VERSION ""

NS_ :

BS_:

BU_: INV VCU BMS U2C

BO_ 3221225472 VECTOR__INDEPENDENT_SIG_MSG: 0 Vector__XXX
 SG_ INV_Buffer_Record : 0|8@1+ (1,0) [0|255] "" Vector__XXX
 SG_ INV_Buffer_Segment : 8|8@1+ (1,0) [0|5] "" Vector__XXX
 SG_ INV_Diag_Data_1 : 16|16@1- (1,0) [-32768|32767] "" Vector__XXX
 SG_ INV_Diag_Data_2 : 32|16@1- (1,0) [-32768|32767] "" Vector__XXX
 SG_ INV_Diag_Data_3 : 48|16@1- (1,0) [-32768|32767] "" Vector__XXX

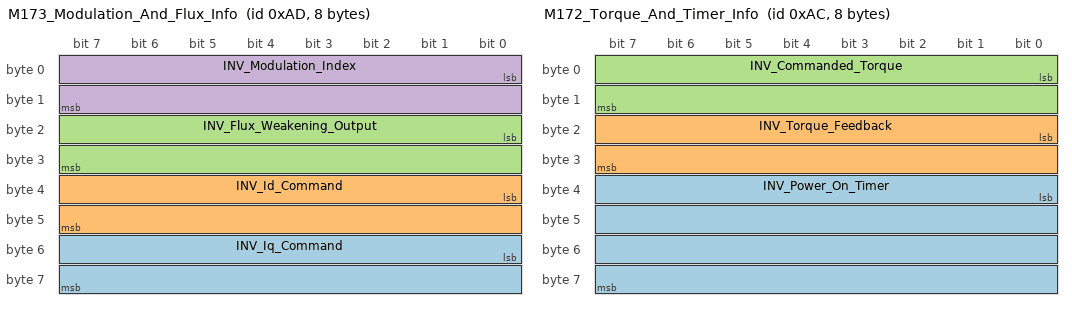
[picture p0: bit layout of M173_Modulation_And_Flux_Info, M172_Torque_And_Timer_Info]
BO_ 173 M173_Modulation_And_Flux_Info: 8 INV
 SG_ INV_Iq_Command : 48|16@1- (0.1,0) [-3276.8|3276.7] "current:A" VCU_Inverter_Ext
 SG_ INV_Id_Command : 32|16@1- (0.1,0) [-3276.8|3276.7] "current:A" VCU_Inverter_Ext
 SG_ INV_Flux_Weakening_Output : 16|16@1- (0.1,0) [-3276.8|3276.7] "current:A" VCU_Inverter_Ext
 SG_ INV_Modulation_Index : 0|16@1- (0.0001,0) [0|3.2767] "" VCU_Inverter_Ext

BO_ 172 M172_Torque_And_Timer_Info: 8 INV
 SG_ INV_Power_On_Timer : 32|32@1+ (0.003,0) [0|12884800] "time:sec" VCU_Inverter_Ext
 SG_ INV_Torque_Feedback : 16|16@1- (0.1,0) [-3276.8|3276.7] "torque:N.m" VCU_Inverter_Ext
 SG_ INV_Commanded_Torque : 0|16@1- (0.1,0) [-3276.8|3276.7] "torque:N.m" VCU_Inverter_Ext

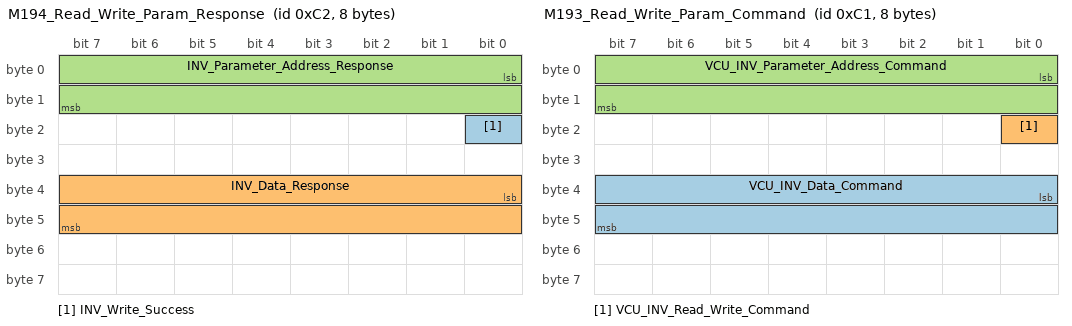
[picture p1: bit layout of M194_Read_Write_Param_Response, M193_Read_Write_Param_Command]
BO_ 194 M194_Read_Write_Param_Response: 8 INV
 SG_ INV_Write_Success : 16|1@1+ (1,0) [0|1] "" VCU_Inverter_Ext
 SG_ INV_Data_Response : 32|16@1- (1,0) [-32768|32767] "" VCU_Inverter_Ext
 SG_ INV_Parameter_Address_Response : 0|16@1+ (1,0) [0|65535] "" VCU_Inverter_Ext

BO_ 193 M193_Read_Write_Param_Command: 8 VCU
 SG_ VCU_INV_Data_Command : 32|16@1- (1,0) [-32768|32767] "" INV
 SG_ VCU_INV_Read_Write_Command : 16|1@1+ (1,0) [0|1] "" INV
 SG_ VCU_INV_Parameter_Address_Command : 0|16@1+ (1,0) [0|65535] "" INV

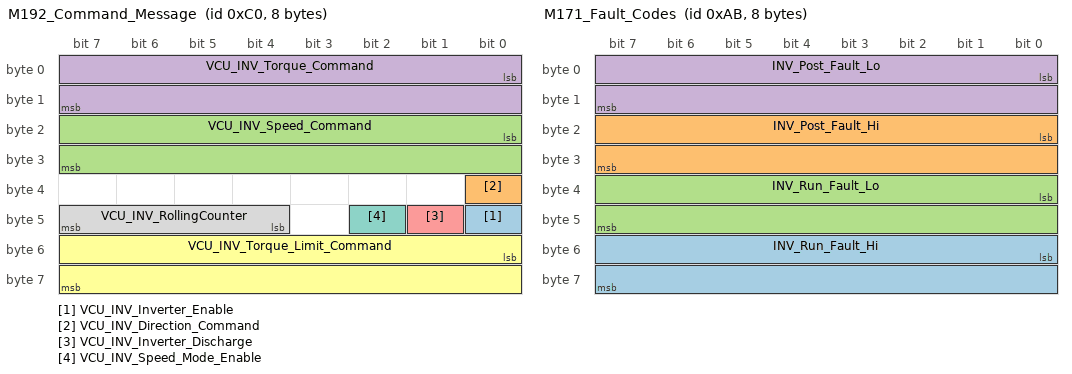
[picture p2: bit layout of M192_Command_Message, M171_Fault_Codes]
BO_ 192 M192_Command_Message: 8 VCU
 SG_ VCU_INV_Inverter_Enable : 40|1@1+ (1,0) [0|1] "Bit" INV
 SG_ VCU_INV_Direction_Command : 32|1@1+ (1,0) [0|1] "Bit" INV
 SG_ VCU_INV_Speed_Command : 16|16@1- (1,0) [-32768|32767] "rpm" INV
 SG_ VCU_INV_Torque_Command : 0|16@1- (0.1,0) [-3276.8|3276.7] "torque:N.m" INV
 SG_ VCU_INV_Inverter_Discharge : 41|1@1+ (1,0) [0|1] "" INV
 SG_ VCU_INV_Torque_Limit_Command : 48|16@1- (0.1,0) [-3276.8|3276.7] "torque:N.m" INV
 SG_ VCU_INV_Speed_Mode_Enable : 42|1@1+ (1,0) [0|1] "" INV
 SG_ VCU_INV_RollingCounter : 44|4@1+ (1,0) [0|15] "" INV

BO_ 171 M171_Fault_Codes: 8 INV
 SG_ INV_Run_Fault_Hi : 48|16@1+ (1,0) [0|65535] "" VCU_Inverter_Ext
 SG_ INV_Post_Fault_Hi : 16|16@1+ (1,0) [0|65535] "" VCU_Inverter_Ext
 SG_ INV_Run_Fault_Lo : 32|16@1+ (1,0) [0|65535] "" VCU_Inverter_Ext
 SG_ INV_Post_Fault_Lo : 0|16@1+ (1,0) [0|65535] "" VCU_Inverter_Ext

BO_ 170 M170_Internal_States: 8 INV
 SG_ INV_Direction_Command : 56|1@1+ (1,0) [0|1] "" VCU_Inverter_Ext
 SG_ INV_Inverter_Enable_State : 48|1@1+ (1,0) [0|1] "" VCU_Inverter_Ext
 SG_ INV_Relay_3_Status : 26|1@1+ (1,0) [0|1] "" VCU_Inverter_Ext
 SG_ INV_Relay_4_Status : 27|1@1+ (1,0) [0|1] "" VCU_Inverter_Ext
 SG_ INV_Relay_2_Status : 25|1@1+ (1,0) [0|1] "" VCU_Inverter_Ext
 SG_ INV_Inverter_Run_Mode : 32|1@1+ (1,0) [0|1] "" VCU_Inverter_Ext
 SG_ INV_Inverter_Command_Mode : 40|1@1+ (1,0) [0|1] "" VCU_Inverter_Ext
 SG_ INV_Relay_1_Status : 24|1@1+ (1,0) [0|1] "" VCU_Inverter_Ext
 SG_ INV_Inverter_State : 16|8@1+ (1,0) [0|255] "" VCU_Inverter_Ext
 SG_ INV_VSM_State : 0|8@1+ (1,0) [0|15] "" VCU_Inverter_Ext
 SG_ INV_Inverter_Enable_Lockout : 55|1@1+ (1,0) [0|1] "" VCU_Inverter_Ext
 SG_ INV_Inverter_Discharge_State : 37|3@1+ (1,0) [0|7] "" VCU_Inverter_Ext
 SG_ INV_Relay_5_Status : 28|1@1+ (1,0) [0|1] "" VCU_Inverter_Ext
 SG_ INV_Relay_6_Status : 29|1@1+ (1,0) [0|1] "" VCU_Inverter_Ext
 SG_ INV_BMS_Active : 57|1@1+ (1,0) [0|1] "" VCU_Inverter_Ext
 SG_ INV_BMS_Torque_Limiting : 58|1@1+ (1,0) [0|1] "" VCU_Inverter_Ext
 SG_ INV_Max_Speed_Limiting : 59|1@1+ (1,0) [0|1] "" VCU_Inverter_Ext
 SG_ INV_Low_Speed_Limiting : 61|1@1+ (1,0) [0|1] "" VCU_Inverter_Ext
 SG_ INV_Rolling_Counter : 44|4@1+ (1,0) [0|15] "" VCU_Inverter_Ext
 SG_ INV_PWM_Frequency : 8|8@1+ (1,0) [0|255] "kHz" VCU_Inverter_Ext
 SG_ INV_Start_Mode_Active : 54|1@1+ (1,0) [0|1] "" VCU_Inverter_Ext

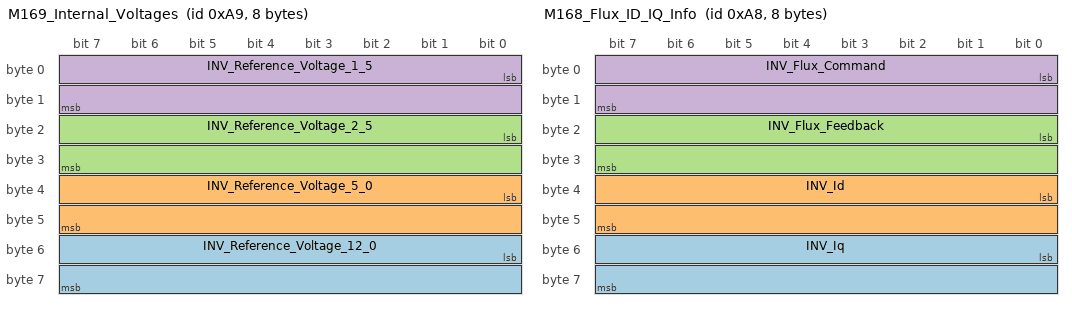
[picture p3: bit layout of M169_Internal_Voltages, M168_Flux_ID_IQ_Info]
BO_ 169 M169_Internal_Voltages: 8 INV
 SG_ INV_Reference_Voltage_12_0 : 48|16@1- (0.01,0) [-327.68|327.67] "voltage:V" VCU_Inverter_Ext
 SG_ INV_Reference_Voltage_5_0 : 32|16@1- (0.01,0) [-327.68|327.67] "voltage:V" VCU_Inverter_Ext
 SG_ INV_Reference_Voltage_2_5 : 16|16@1- (0.01,0) [-327.68|327.67] "voltage:V" VCU_Inverter_Ext
 SG_ INV_Reference_Voltage_1_5 : 0|16@1- (0.01,0) [-327.68|327.67] "voltage:V" VCU_Inverter_Ext

BO_ 168 M168_Flux_ID_IQ_Info: 8 INV
 SG_ INV_Iq : 48|16@1- (0.1,0) [-3276.8|3276.7] "current:A" VCU_Inverter_Ext
 SG_ INV_Id : 32|16@1- (0.1,0) [-3276.8|3276.7] "current:A" VCU_Inverter_Ext
 SG_ INV_Flux_Feedback : 16|16@1- (0.001,0) [-32.768|32.767] "flux:Wb" VCU_Inverter_Ext
 SG_ INV_Flux_Command : 0|16@1- (0.001,0) [-32.768|32.767] "flux:Wb" VCU_Inverter_Ext

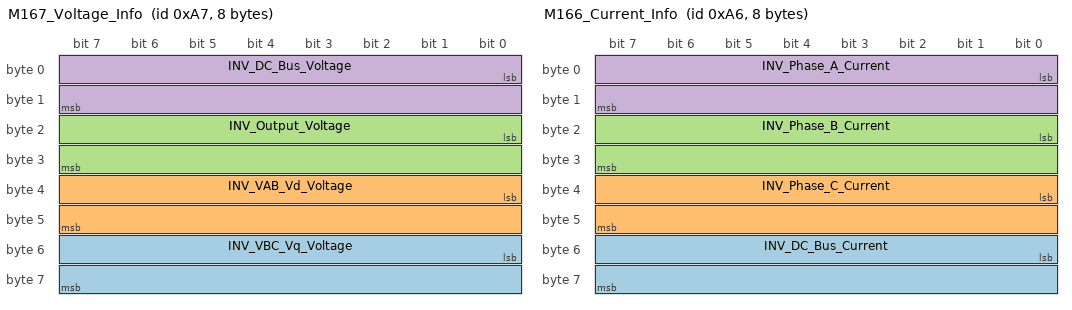
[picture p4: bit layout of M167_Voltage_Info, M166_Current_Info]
BO_ 167 M167_Voltage_Info: 8 INV
 SG_ INV_VBC_Vq_Voltage : 48|16@1- (0.1,0) [-3276.8|3276.7] "voltage:V" VCU_Inverter_Ext
 SG_ INV_VAB_Vd_Voltage : 32|16@1- (0.1,0) [-3276.8|3276.7] "voltage:V" VCU_Inverter_Ext
 SG_ INV_Output_Voltage : 16|16@1- (0.1,0) [-3276.8|3276.7] "voltage:V" VCU_Inverter_Ext
 SG_ INV_DC_Bus_Voltage : 0|16@1- (0.1,0) [-3276.8|3276.7] "voltage:V" VCU_Inverter_Ext

BO_ 166 M166_Current_Info: 8 INV
 SG_ INV_DC_Bus_Current : 48|16@1- (0.1,0) [-3276.8|3276.7] "current:A" VCU_Inverter_Ext
 SG_ INV_Phase_C_Current : 32|16@1- (0.1,0) [-3276.8|3276.7] "current:A" VCU_Inverter_Ext
 SG_ INV_Phase_B_Current : 16|16@1- (0.1,0) [-3276.8|3276.7] "current:A" VCU_Inverter_Ext
 SG_ INV_Phase_A_Current : 0|16@1- (0.1,0) [-3276.8|3276.7] "current:A" VCU_Inverter_Ext

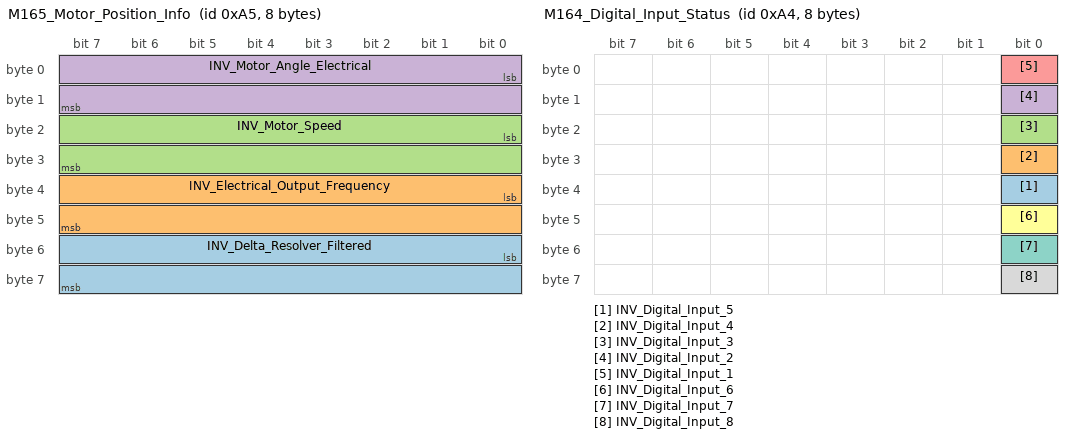
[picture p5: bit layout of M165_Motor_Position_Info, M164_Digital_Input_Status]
BO_ 165 M165_Motor_Position_Info: 8 INV
 SG_ INV_Delta_Resolver_Filtered : 48|16@1- (0.1,0) [-3276.8|3276.7] "angle:deg" VCU_Inverter_Ext
 SG_ INV_Electrical_Output_Frequency : 32|16@1- (0.1,0) [-3276.8|3276.7] "frequency:Hz" VCU_Inverter_Ext
 SG_ INV_Motor_Speed : 16|16@1- (1,0) [-32768|32767] "angular_speed:rpm" VCU_Inverter_Ext
 SG_ INV_Motor_Angle_Electrical : 0|16@1+ (0.1,0) [0|6553.5] "angle:deg" VCU_Inverter_Ext

BO_ 164 M164_Digital_Input_Status: 8 INV
 SG_ INV_Digital_Input_5 : 32|1@1+ (1,0) [0|1] "" VCU_Inverter_Ext
 SG_ INV_Digital_Input_4 : 24|1@1+ (1,0) [0|1] "" VCU_Inverter_Ext
 SG_ INV_Digital_Input_3 : 16|1@1+ (1,0) [0|1] "" VCU_Inverter_Ext
 SG_ INV_Digital_Input_2 : 8|1@1+ (1,0) [0|1] "" VCU_Inverter_Ext
 SG_ INV_Digital_Input_1 : 0|1@1+ (1,0) [0|1] "" VCU_Inverter_Ext
 SG_ INV_Digital_Input_6 : 40|1@1+ (1,0) [0|1] "" VCU_Inverter_Ext
 SG_ INV_Digital_Input_7 : 48|1@1+ (1,0) [0|1] "" VCU_Inverter_Ext
 SG_ INV_Digital_Input_8 : 56|1@1+ (1,0) [0|1] "" VCU_Inverter_Ext

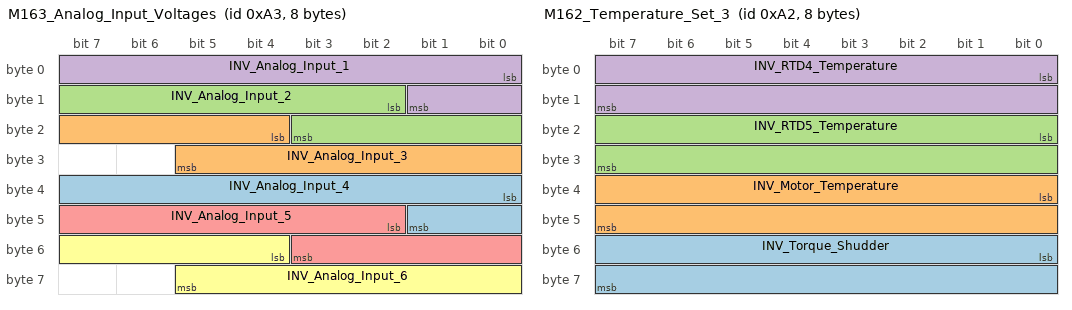
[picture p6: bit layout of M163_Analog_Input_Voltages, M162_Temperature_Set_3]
BO_ 163 M163_Analog_Input_Voltages: 8 INV
 SG_ INV_Analog_Input_4 : 32|10@1+ (0.01,0) [0|10.23] "voltage:V" VCU_Inverter_Ext
 SG_ INV_Analog_Input_3 : 20|10@1+ (0.01,0) [0|10.23] "voltage:V" VCU_Inverter_Ext
 SG_ INV_Analog_Input_2 : 10|10@1+ (0.01,0) [0|10.23] "voltage:V" VCU_Inverter_Ext
 SG_ INV_Analog_Input_1 : 0|10@1+ (0.01,0) [0|10.23] "voltage:V" VCU_Inverter_Ext
 SG_ INV_Analog_Input_5 : 42|10@1+ (0.01,0) [0|10.23] "voltage:V" VCU_Inverter_Ext
 SG_ INV_Analog_Input_6 : 52|10@1+ (0.01,0) [0|10.23] "voltage:V" VCU_Inverter_Ext

BO_ 162 M162_Temperature_Set_3: 8 INV
 SG_ INV_Torque_Shudder : 48|16@1- (0.1,0) [-3276.8|3276.7] "torque:N.m" VCU_Inverter_Ext
 SG_ INV_Motor_Temperature : 32|16@1- (0.1,0) [-3276.8|3276.7] "temperature:C" VCU_Inverter_Ext
 SG_ INV_RTD5_Temperature : 16|16@1- (0.1,0) [-3276.8|3276.7] "temperature:C" VCU_Inverter_Ext
 SG_ INV_RTD4_Temperature : 0|16@1- (0.1,0) [-3276.8|3276.7] "temperature:C" VCU_Inverter_Ext

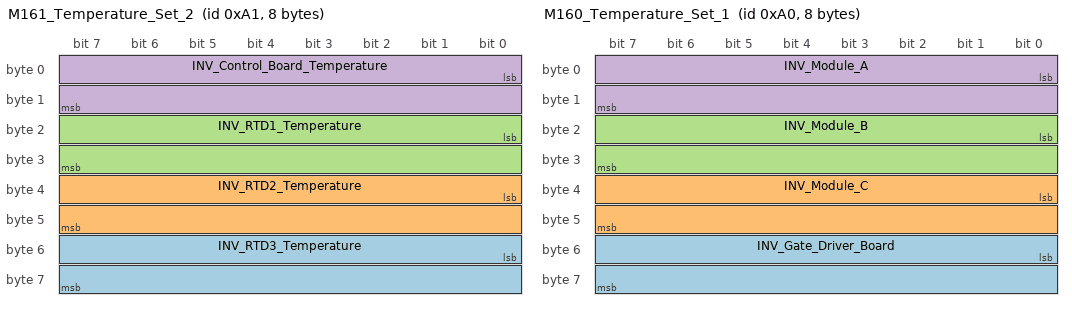
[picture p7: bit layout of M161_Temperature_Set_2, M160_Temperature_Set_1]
BO_ 161 M161_Temperature_Set_2: 8 INV
 SG_ INV_RTD3_Temperature : 48|16@1- (0.1,0) [-3276.8|3276.7] "temperature:C" VCU_Inverter_Ext
 SG_ INV_RTD2_Temperature : 32|16@1- (0.1,0) [-3276.8|3276.7] "temperature:C" VCU_Inverter_Ext
 SG_ INV_RTD1_Temperature : 16|16@1- (0.1,0) [-3276.8|3276.7] "temperature:C" VCU_Inverter_Ext
 SG_ INV_Control_Board_Temperature : 0|16@1- (0.1,0) [-3276.8|3276.7] "temperature:C" VCU_Inverter_Ext

BO_ 160 M160_Temperature_Set_1: 8 INV
 SG_ INV_Gate_Driver_Board : 48|16@1- (0.1,0) [-3276.8|3276.7] "temperature:C" VCU_Inverter_Ext
 SG_ INV_Module_C : 32|16@1- (0.1,0) [-3276.8|3276.7] "temperature:C" VCU_Inverter_Ext
 SG_ INV_Module_B : 16|16@1- (0.1,0) [-3276.8|3276.7] "temperature:C" VCU_Inverter_Ext
 SG_ INV_Module_A : 0|16@1- (0.1,0) [-3276.8|3276.7] "temperature:C" VCU_Inverter_Ext

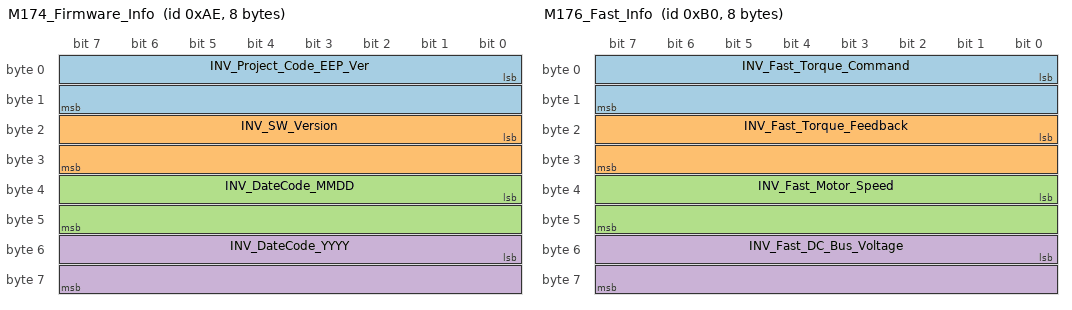
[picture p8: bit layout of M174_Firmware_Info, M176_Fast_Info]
BO_ 174 M174_Firmware_Info: 8 INV
 SG_ INV_Project_Code_EEP_Ver : 0|16@1+ (1,0) [0|65535] "" VCU_Inverter_Ext
 SG_ INV_SW_Version : 16|16@1+ (1,0) [0|65535] "" VCU_Inverter_Ext
 SG_ INV_DateCode_MMDD : 32|16@1+ (1,0) [0|65535] "" VCU_Inverter_Ext
 SG_ INV_DateCode_YYYY : 48|16@1+ (1,0) [0|65535] "" VCU_Inverter_Ext

BO_ 176 M176_Fast_Info: 8 INV
 SG_ INV_Fast_Torque_Command : 0|16@1- (0.1,0) [-3276.8|3276.7] "torque:N.m" VCU_Inverter_Ext
 SG_ INV_Fast_Torque_Feedback : 16|16@1- (0.1,0) [-3276.8|3276.7] "torque:N.m" VCU_Inverter_Ext
 SG_ INV_Fast_Motor_Speed : 32|16@1- (1,0) [-32768|32767] "angular_speed:rpm" VCU_Inverter_Ext
 SG_ INV_Fast_DC_Bus_Voltage : 48|16@1- (0.1,0) [-3276.8|3276.7] "voltage:V" VCU_Inverter_Ext

BO_ 514 BMS_Current_Limit: 8 BMS
 SG_ INV_Max_Discharge_Current : 0|16@1+ (1,0) [0|1000] "current:A" VCU_Inverter_Ext
 SG_ INV_Max_Charge_Current : 16|16@1+ (1,0) [0|1000] "current:A" VCU_Inverter_Ext

CM_ BU_ INV "Rinehart PM100DX Motor Inverter";
CM_ BU_ VCU "Vehicle Control Unit";
CM_ BU_ BMS "Battery Management System";
CM_ BU_ U2C "Delphi DC/DC Converter";
CM_ SG_ 173 INV_Iq_Command "The commanded Q-axis current";
CM_ SG_ 173 INV_Id_Command "The commanded D-axis current";
CM_ SG_ 173 INV_Flux_Weakening_Output "This is the current output of the flux regulator.";
CM_ SG_ 173 INV_Modulation_Index "This is the modulation index. The scale factor is x100. To get the actual modulation index divide the value by 100.";
CM_ SG_ 172 INV_Power_On_Timer "Updated every 3 msec. This will roll over in approximately 150 days!";
CM_ SG_ 172 INV_Torque_Feedback "Estimated motor torque feedback";
CM_ SG_ 172 INV_Commanded_Torque "The commanded Torque";
CM_ BO_ 194 "The inverter response to each Parameter message that is received.";
CM_ SG_ 194 INV_Write_Success "0=Write failure, 1=Success";
CM_ SG_ 194 INV_Data_Response "All EEPROM data is 16 bits and is contained in bytes 4 and 5. Bytes 6 and 7 should be ignored.";
CM_ SG_ 194 INV_Parameter_Address_Response "Valid EEPROM Parameter CAN addresses are between 100 and 499.";
CM_ BO_ 193 "Parameter Message sent as needed by VCU to request info, change EEPROM, or command a function.";
CM_ BO_ 192 "Command Message from VCU to Inverter for torque/speed control.";
CM_ SG_ 171 INV_Run_Fault_Hi "Each bit represents a fault. Please refer to PM100 Users Manual for details.";
CM_ SG_ 171 INV_Post_Fault_Hi "Each bit represents a fault. Please refer to PM100 Users Manual for details.";
CM_ SG_ 171 INV_Run_Fault_Lo "Each bit represents a fault. Please refer to PM100 Users Manual for details.";
CM_ SG_ 171 INV_Post_Fault_Lo "Each bit represents a fault. Please refer to PM100 Users Manual for details.";
CM_ SG_ 170 INV_Direction_Command "1 = Forward, 0 = Reverse if enabled or Stopped if disabled";
CM_ SG_ 170 INV_Inverter_Enable_State "0=Inverter Disabled, 1=Inverter Enabled";
CM_ SG_ 170 INV_Relay_1_Status "0=OFF, 1=ON";
CM_ SG_ 170 INV_Relay_2_Status "0=OFF, 1=ON";
CM_ SG_ 170 INV_Relay_3_Status "0=OFF, 1=ON";
CM_ SG_ 170 INV_Relay_4_Status "0=OFF, 1=ON";
CM_ SG_ 170 INV_Relay_5_Status "0=OFF, 1=ON";
CM_ SG_ 170 INV_Relay_6_Status "0=OFF, 1=ON";
CM_ SG_ 170 INV_Inverter_Run_Mode "0=Torque Mode, 1=Speed Mode";
CM_ SG_ 170 INV_Inverter_Command_Mode "0=CAN mode, 1=VSM mode";
CM_ SG_ 170 INV_Inverter_State "Different states for the inverter state machine";
CM_ SG_ 170 INV_VSM_State "Different states for the vehicle state machine";
CM_ SG_ 170 INV_Inverter_Enable_Lockout "0=Lockout Disabled, 1=Lockout Enabled";
CM_ SG_ 170 INV_Inverter_Discharge_State "0 = Disabled, 1 = Enabled, 2 = Speed Check, 3 = Active, 4 = Complete";
CM_ SG_ 170 INV_BMS_Active "0 = BMS Not Active, 1 = BMS Active";
CM_ SG_ 170 INV_BMS_Torque_Limiting "0 = Not Limiting, 1 = Limiting";
CM_ SG_ 170 INV_Max_Speed_Limiting "0 = Not Limiting, 1 = torque limiting due to maximum speed";
CM_ SG_ 170 INV_Low_Speed_Limiting "0 = Not Limiting, 1 = Current limiting due to low motor speed";
CM_ SG_ 170 INV_Rolling_Counter "The current rolling counter value.";
CM_ SG_ 170 INV_PWM_Frequency "The inverter PWM frequency";
CM_ SG_ 170 INV_Start_Mode_Active "If in Key Switch Mode 1 then indicates status of Start input being applied. 0 = not active, 1 = active";
CM_ BO_ 514 "Message sent by BMS for inverter DC current limiting.";
CM_ SG_ 514 INV_Max_Discharge_Current "Maximum discharge current from BMS";
CM_ SG_ 514 INV_Max_Charge_Current "Maximum charge current from BMS";
CM_ BO_ 176 "Fast telemetry message - 5ms cycle. To enable, set CAN ACTIVE MSGS HI WORD to 0xFFFE.";
BA_DEF_ BO_  "GenMsgCycleTime" INT 0 100000;
BA_DEF_  "BusType" STRING ;
BA_DEF_DEF_  "GenMsgCycleTime" 0;
BA_DEF_DEF_  "BusType" "CAN";
BA_ "GenMsgCycleTime" BO_ 176 5;
BA_ "GenMsgCycleTime" BO_ 172 10;
BA_ "GenMsgCycleTime" BO_ 168 10;
BA_ "GenMsgCycleTime" BO_ 167 10;
BA_ "GenMsgCycleTime" BO_ 166 10;
BA_ "GenMsgCycleTime" BO_ 165 10;
BA_ "GenMsgCycleTime" BO_ 164 100;
BA_ "GenMsgCycleTime" BO_ 163 100;
BA_ "GenMsgCycleTime" BO_ 162 100;
BA_ "GenMsgCycleTime" BO_ 161 100;
BA_ "GenMsgCycleTime" BO_ 160 100;
BA_ "GenMsgCycleTime" BO_ 171 100;
BA_ "GenMsgCycleTime" BO_ 170 100;
BA_ "GenMsgCycleTime" BO_ 169 100;
BA_ "GenMsgCycleTime" BO_ 174 100;
BA_ "GenMsgCycleTime" BO_ 192 5;
VAL_ 170 INV_Inverter_State 0 "Power up" 1 "Stop" 2 "Open Loop" 3 "Closed Loop" 4 "Internal State" 5 "Internal State" 6 "Internal State" 7 "Internal State" 8 "Idle Run" 9 "Idle Stop" 10 "Internal State" 11 "Intern State" 12 "Internal State" ;
VAL_ 170 INV_VSM_State 0 "VSM Start State" 1 "Pre-Charge Init state" 2 "pre-charge active state" 3 "pre-charge complete state" 4 "VSM wait state" 5 "VSM ready state" 6 "Motor Running State" 7 "blink fault code state" 14 "Shutdown state for Key Switch Mode 1" 15 "Reset the inverter" ;
VAL_ 192 VCU_INV_Direction_Command 0 "Reverse" 1 "Forward" ;
VAL_ 192 VCU_INV_Inverter_Enable 0 "Disabled" 1 "Enabled" ;
